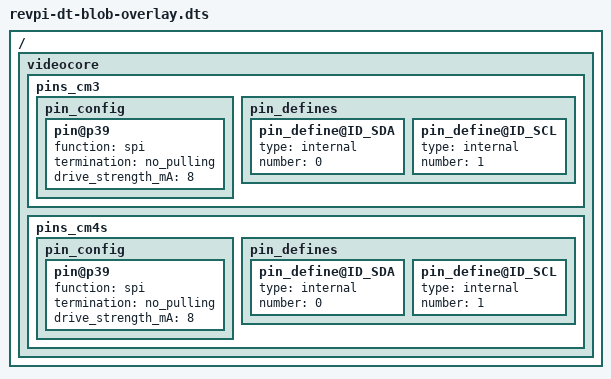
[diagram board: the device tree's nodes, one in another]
/*
 * Device tree blob overlay for Revolution Pi by KUNBUS
 *
 * For all RevPi models with a HAT EEEPROM
 */

#include "rpi-dt-blob-overlay.dts"


/ {
	videocore {
		pins_cm3 {
			pin_config {
				/* Increase drive strength in order to improve the signal quality (eg. SPI CLK on Core 3 and Connect)
				 * NOTE: This will increase the drive strength for the whole GPIO bank 1 and not only pin 39
				 */
				pin@p39 { function = "spi"; termination = "no_pulling"; drive_strength_mA = < 8 >; };
			}; // pin_config
			pin_defines {
				/* For redesigned Core and Connect with HATs */
				pin_define@ID_SDA {
					type = "internal";
					number = <0>;
				};
				pin_define@ID_SCL {
					type = "internal";
					number = <1>;
				};
			}; // pin_defines
		};

		pins_cm4s {
			pin_config {
				/* Increase drive strength in order to improve the signal quality (eg. SPI CLK on Core S and Connect S)
				 * NOTE: This will increase the drive strength for the whole GPIO bank 1 and not only pin 39
				 */
				pin@p39 { function = "spi"; termination = "no_pulling"; drive_strength_mA = < 8 >; };
			}; // pin_config
			pin_defines {
				/* For Core S/SE and Connect S/SE with HATs */
				pin_define@ID_SDA {
					type = "internal";
					number = <0>;
				};
				pin_define@ID_SCL {
					type = "internal";
					number = <1>;
				};
			}; // pin_defines
		};
	};
};
